# STM32H7B0 register map
File version: 2.3
CPU: CM7 r0p1, little endian, MPU, FPU, 4 interrupt priority bits
Registers are 32-bit, read-write, reset 0x0 unless marked. A register's access mark holds for its fields unless they carry their own. Offsets are from the block's base; [hi:lo] are bit positions.

## SPDIFRX — Receiver Interface
Base 0x40004000
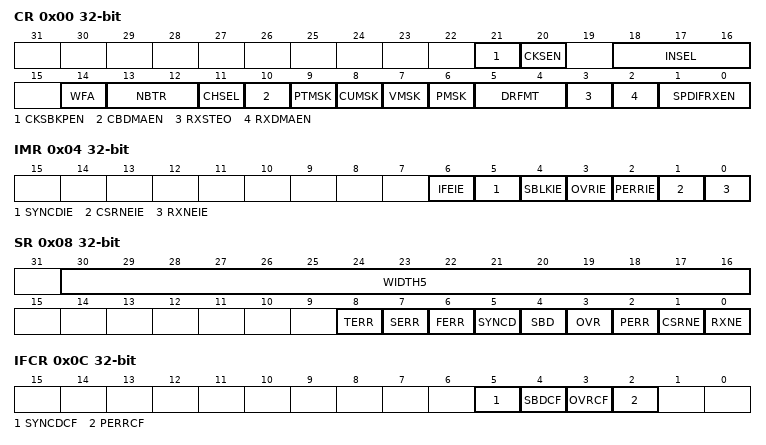
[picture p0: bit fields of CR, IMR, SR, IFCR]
0x00 CR — Control register
  [21] CKSBKPEN — Backup Symbol Clock Enable
  [20] CKSEN — Symbol Clock Enable
  [18:16] INSEL — input selection
  [14] WFA — Wait For Activity
  [13:12] NBTR — Maximum allowed re-tries during synchronization phase
  [11] CHSEL — Channel Selection
  [10] CBDMAEN — Control Buffer DMA ENable for control flow
  [9] PTMSK — Mask of Preamble Type bits
  [8] CUMSK — Mask of channel status and user bits
  [7] VMSK — Mask of Validity bit
  [6] PMSK — Mask Parity error bit
  [5:4] DRFMT — RX Data format
  [3] RXSTEO — STerEO Mode
  [2] RXDMAEN — Receiver DMA ENable for data flow
  [1:0] SPDIFRXEN — Peripheral Block Enable
0x04 IMR — Interrupt mask register
  [6] IFEIE — Serial Interface Error Interrupt Enable
  [5] SYNCDIE — Synchronization Done
  [4] SBLKIE — Synchronization Block Detected Interrupt Enable
  [3] OVRIE — Overrun error Interrupt Enable
  [2] PERRIE — Parity error interrupt enable
  [1] CSRNEIE — Control Buffer Ready Interrupt Enable
  [0] RXNEIE — RXNE interrupt enable
0x08 SR ro — Status register
  [30:16] WIDTH5 — Duration of 5 symbols counted with SPDIF_CLK
  [8] TERR — Time-out error
  [7] SERR — Synchronization error
  [6] FERR — Framing error
  [5] SYNCD — Synchronization Done
  [4] SBD — Synchronization Block Detected
  [3] OVR — Overrun error
  [2] PERR — Parity error
  [1] CSRNE — Control Buffer register is not empty
  [0] RXNE — Read data register not empty
0x0C IFCR wo — Interrupt Flag Clear register
  [5] SYNCDCF — Clears the Synchronization Done flag
  [4] SBDCF — Clears the Synchronization Block Detected flag
  [3] OVRCF — Clears the Overrun error flag
  [2] PERRCF — Clears the Parity error flag
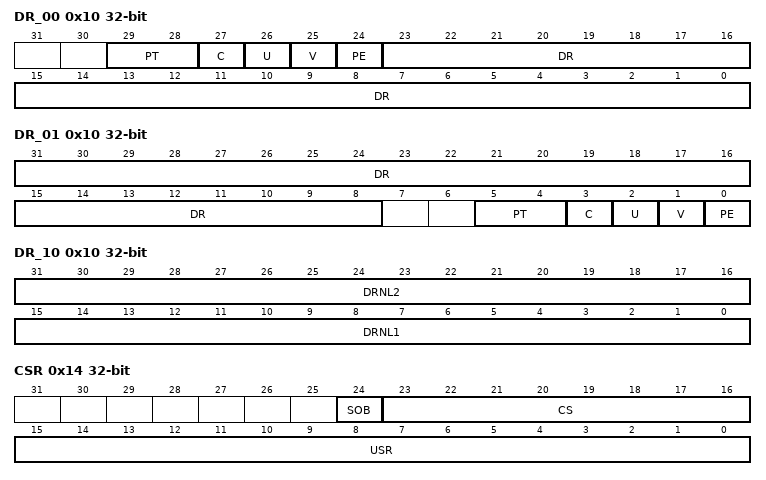
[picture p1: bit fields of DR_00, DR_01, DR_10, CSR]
0x10 DR_00 ro — Data input register
  [29:28] PT — Preamble Type
  [27] C — Channel Status bit
  [26] U — User bit
  [25] V — Validity bit
  [24] PE — Parity Error bit
  [23:0] DR — Parity Error bit
0x10 DR_01 ro (alternate view of DR_00) — Data input register
  [31:8] DR — Data value
  [5:4] PT — Preamble Type
  [3] C — Channel Status bit
  [2] U — User bit
  [1] V — Validity bit
  [0] PE — Parity Error bit
0x10 DR_10 ro — Data input register
  [31:16] DRNL2 — Data value
  [15:0] DRNL1 — Data value
0x14 CSR ro — Channel Status register
  [24] SOB — Start Of Block
  [23:16] CS — Channel A status information
  [15:0] USR — User data information
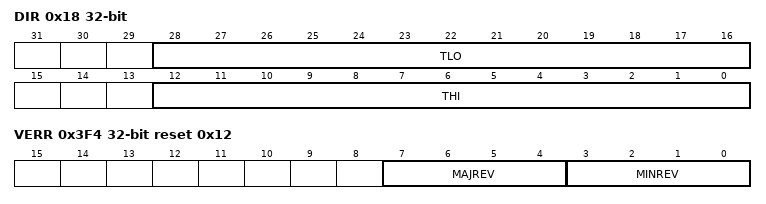
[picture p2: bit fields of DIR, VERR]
0x18 DIR ro — Debug Information register
  [28:16] TLO — Threshold LOW
  [12:0] THI — Threshold HIGH
0x3F4 VERR ro reset 0x12 — SPDIFRX version register
  [7:4] MAJREV — Major revision
  [3:0] MINREV — Minor revision
0x3F8 IDR ro reset 0x130041 — SPDIFRX identification register
  [31:0] ID — SPDIFRX identifier
0x3FC SIDR ro reset 0xA3C5DD01 — SPDIFRX size identification register
  [31:0] SID — Size identification

## CRC — Cryptographic processor
Base 0x40023000
0x00 DR reset 0xFFFFFFFF — Data register
  [31:0] DR — Data Register
0x00 DR8 8-bit reset 0xFF (alternate view of DR) — Data register - byte sized
  [7:0] DR8 — Data register bits
0x00 DR16 16-bit reset 0xFFFF (alternate view of DR) — Data register - half-word sized
  [15:0] DR16 — Data register bits
0x04 IDR — Independent Data register
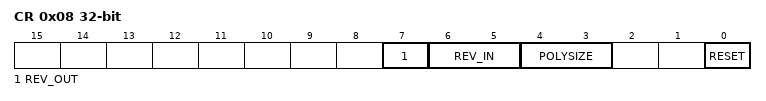
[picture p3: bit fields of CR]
0x08 CR access per field — Control register
  [7] REV_OUT rw — Reverse output data
    0=Normal (Bit order not affected); 1=Reversed (Bit reversed output)
  [6:5] REV_IN rw — Reverse input data
    0=Normal (Bit order not affected); 1=Byte (Bit reversal done by byte); 2=HalfWord (Bit reversal done by half-word); 3=Word (Bit reversal done by word)
  [4:3] POLYSIZE rw — Polynomial size
    0=32-bit polynomial; 1=16-bit polynomial; 2=8-bit polynomial; 3=7-bit polynomial
  [0] RESET wo — RESET bit
    1=Resets the CRC calculation unit and sets the data register to 0xFFFF FFFF
0x10 INIT — Initial CRC value
  [31:0] INIT — Programmable initial CRC value
0x14 POL — CRC polynomial
  [31:0] POL — Programmable polynomial
